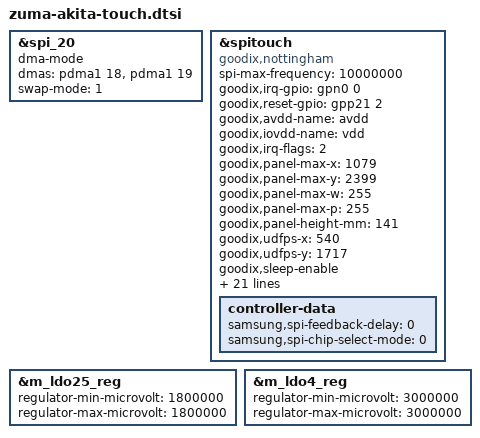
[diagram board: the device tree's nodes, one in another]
// SPDX-License-Identifier: GPL-2.0-only
/*
 * Google Akita touch device tree source
 *
 * Copyright 2022 Google LLC.
 *
 */

#include "zuma/zuma-common-touch.dtsi"

&spi_20 {
	status = "okay";
	dma-mode;
	dmas = <&pdma1 18 &pdma1 19>;
	swap-mode = <1>;
};

&spitouch {
	status = "ok";
	compatible = "goodix,nottingham";

	spi-max-frequency = <10000000>;

	goodix,irq-gpio = <&gpn0 0 0>;
	goodix,reset-gpio = <&gpp21 2 0>;
	goodix,avdd-name = "avdd";
	goodix,iovdd-name = "vdd";
	goodix,irq-flags = <2>; /* 1:trigger rising, 2:trigger falling;*/
	goodix,panel-max-x = <1079>;
	goodix,panel-max-y = <2399>;
	goodix,panel-max-w = <255>;
	goodix,panel-max-p = <255>;
	goodix,panel-height-mm = <141>;
	goodix,udfps-x = <540>;
	goodix,udfps-y = <1717>;
	goodix,sleep-enable;
	goodix,use-one-binary;

	goog,panel_map = <&google_ak3a 0>,
			<&google_ak3b 1>;

	goog,firmware_names = "goodix_firmware_ak3a.bin",
				"goodix_firmware_ak3b.bin";

	goog,test_limits_names = "goodix_test_limits_ak3a.csv",
				"goodix_test_limits_ak3b.csv";

	goog,offload-enabled;
	goog,v4l2-enabled;
	goog,offload-caps-scan-types = /bits/ 16 <0xC0>;
	goog,offload-caps-context-channel-types = /bits/ 16 <0x0100>;
	goog,touch_offload_ids = /bits/ 8 <'l' '1' '0' '0' 'a' 'k' '3' '0'>;
	goog,display-resolution = /bits/ 16 <1080 2400>;
	goog,channel-num = /bits/ 16 <16 34>;
	goog,tbn-enabled;
	goog,offload-caps-rotation-reporting;
	goog,offload-caps-cancel-reporting;
	goog,offload-caps-coord-filter;
	goog,coord-filter-enabled;

	controller-data {
		samsung,spi-feedback-delay = <0>;
		samsung,spi-chip-select-mode = <0>;
	};
};

&m_ldo25_reg {
	regulator-min-microvolt = <1800000>;
	regulator-max-microvolt = <1800000>;
	/delete-property/ regulator-always-on;
};

&m_ldo4_reg {
	regulator-min-microvolt = <3000000>;
	regulator-max-microvolt = <3000000>;
	/delete-property/ regulator-always-on;
};
